# f28e12x_gpio_ctrl_regs register map
Vendor: Texas Instruments
Peripheral module from a debugger description file (folder C2000).
Address unit: 16 bits
Registers are 32-bit, read-write, no defined reset value unless marked. A register's access mark holds for its fields unless they carry their own. Offsets are as the file gives them; lines under a group give offsets from that group; [hi:lo] are bit positions; {n}, {i} and the like mark numbered series; 'fields as' and 'values as' point back to an identical list; <NAME> marks a mode.

## GPIO_CTRL_REGS — GPIO CTRL Registers
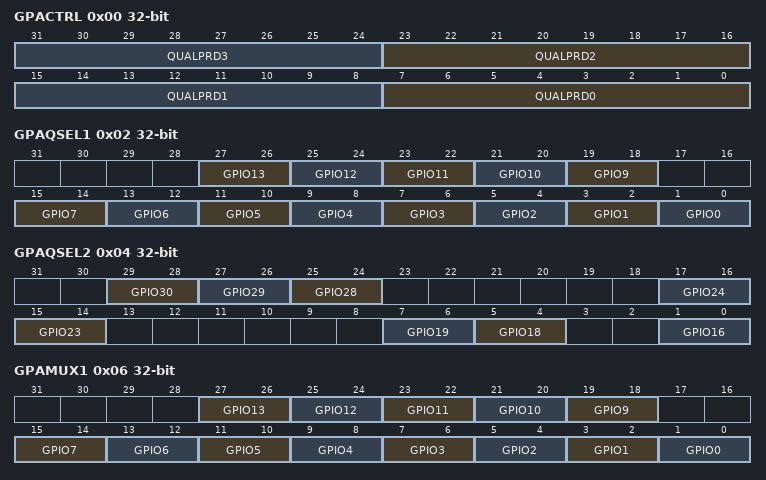
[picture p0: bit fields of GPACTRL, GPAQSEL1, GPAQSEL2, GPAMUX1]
0x00 GPACTRL — GPIO A Qualification Sampling Period Control (GPIO0 to 31)
  [8n+7:8n] QUALPRD{n} (n=0..3) — Qualification sampling period for GPIO{8n} to GPIO{8n+7}
0x02 GPAQSEL1 — GPIO A Qualifier Select 1 Register (GPIO0 to 15)
  [2n+1:2n] GPIO{n} (n=9..13) — Select input qualification type for GPIO{n}
  [2n+1:2n] GPIO{n} (n=0..7) — Select input qualification type for GPIO{n}
0x04 GPAQSEL2 — GPIO A Qualifier Select 2 Register (GPIO16 to 31)
  [29:28] GPIO30 — Select input qualification type for GPIO30
  [27:26] GPIO29 — Select input qualification type for GPIO29
  [25:24] GPIO28 — Select input qualification type for GPIO28
  [17:16] GPIO24 — Select input qualification type for GPIO24
  [15:14] GPIO23 — Select input qualification type for GPIO23
  [7:6] GPIO19 — Select input qualification type for GPIO19
  [5:4] GPIO18 — Select input qualification type for GPIO18
  [1:0] GPIO16 — Select input qualification type for GPIO16
0x06 GPAMUX1 — GPIO A Mux 1 Register (GPIO0 to 15)
  [2n+1:2n] GPIO{n} (n=9..13) — Defines pin-muxing selection for GPIO{n}
  [2n+1:2n] GPIO{n} (n=0..7) — Defines pin-muxing selection for GPIO{n}
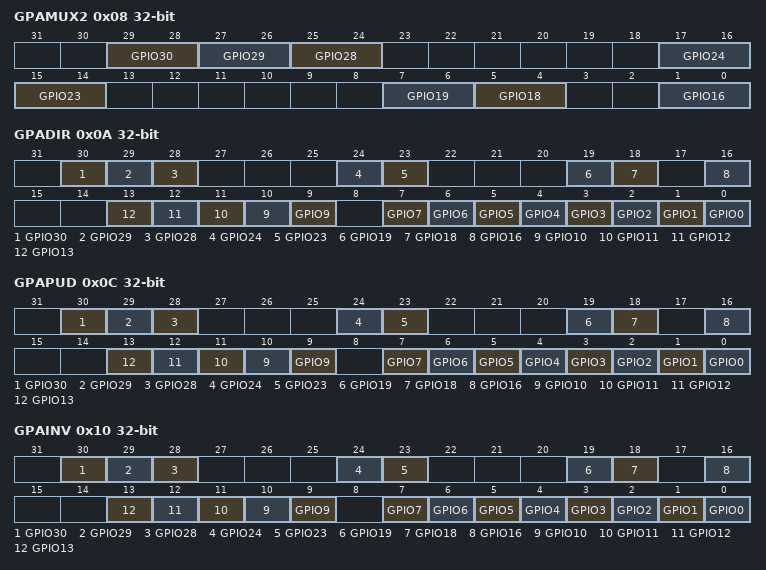
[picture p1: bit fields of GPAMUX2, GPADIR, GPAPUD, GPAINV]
0x08 GPAMUX2 — GPIO A Mux 2 Register (GPIO16 to 31)
  [29:28] GPIO30 — Defines pin-muxing selection for GPIO30
  [27:26] GPIO29 — Defines pin-muxing selection for GPIO29
  [25:24] GPIO28 — Defines pin-muxing selection for GPIO28
  [17:16] GPIO24 — Defines pin-muxing selection for GPIO24
  [15:14] GPIO23 — Defines pin-muxing selection for GPIO23
  [7:6] GPIO19 — Defines pin-muxing selection for GPIO19
  [5:4] GPIO18 — Defines pin-muxing selection for GPIO18
  [1:0] GPIO16 — Defines pin-muxing selection for GPIO16
0x0A GPADIR — GPIO A Direction Register (GPIO0 to 31)
  [30] GPIO30 — Defines direction for this pin in GPIO mode
  [29] GPIO29 — Defines direction for this pin in GPIO mode
  [28] GPIO28 — Defines direction for this pin in GPIO mode
  [24] GPIO24 — Defines direction for this pin in GPIO mode
  [23] GPIO23 — Defines direction for this pin in GPIO mode
  [19] GPIO19 — Defines direction for this pin in GPIO mode
  [18] GPIO18 — Defines direction for this pin in GPIO mode
  [16] GPIO16 — Defines direction for this pin in GPIO mode
  [n] GPIO{n} (n=9..13) — Defines direction for this pin in GPIO mode
  [n] GPIO{n} (n=0..7) — Defines direction for this pin in GPIO mode
0x0C GPAPUD — GPIO A Pull Up Disable Register (GPIO0 to 31)
  [30] GPIO30 — Pull-Up Disable control for this pin
  [29] GPIO29 — Pull-Up Disable control for this pin
  [28] GPIO28 — Pull-Up Disable control for this pin
  [24] GPIO24 — Pull-Up Disable control for this pin
  [23] GPIO23 — Pull-Up Disable control for this pin
  [19] GPIO19 — Pull-Up Disable control for this pin
  [18] GPIO18 — Pull-Up Disable control for this pin
  [16] GPIO16 — Pull-Up Disable control for this pin
  [n] GPIO{n} (n=9..13) — Pull-Up Disable control for this pin
  [n] GPIO{n} (n=0..7) — Pull-Up Disable control for this pin
0x10 GPAINV — GPIO A Input Polarity Invert Registers (GPIO0 to 31)
  [30] GPIO30 — Input inversion control for this pin
  [29] GPIO29 — Input inversion control for this pin
  [28] GPIO28 — Input inversion control for this pin
  [24] GPIO24 — Input inversion control for this pin
  [23] GPIO23 — Input inversion control for this pin
  [19] GPIO19 — Input inversion control for this pin
  [18] GPIO18 — Input inversion control for this pin
  [16] GPIO16 — Input inversion control for this pin
  [n] GPIO{n} (n=9..13) — Input inversion control for this pin
  [n] GPIO{n} (n=0..7) — Input inversion control for this pin
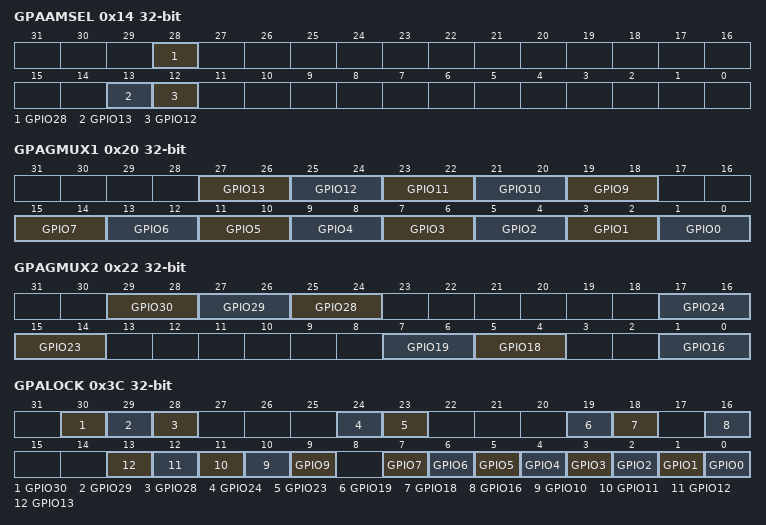
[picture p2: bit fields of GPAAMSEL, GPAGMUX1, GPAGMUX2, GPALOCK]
0x14 GPAAMSEL — GPIO A Analog Mode Select register (GPIO0 to GPIO31)
  [28] GPIO28 — Analog Mode select for this pin
  [13] GPIO13 — Analog Mode select for this pin
  [12] GPIO12 — Analog Mode select for this pin
0x20 GPAGMUX1 — GPIO A Peripheral Group Mux (GPIO0 to 15)
  fields as GPAMUX1
0x22 GPAGMUX2 — GPIO A Peripheral Group Mux (GPIO16 to 31)
  fields as GPAMUX2
0x3C GPALOCK — GPIO A Lock Configuration Register (GPIO0 to 31)
  [30] GPIO30 — Configuration Lock bit for this pin
  [29] GPIO29 — Configuration Lock bit for this pin
  [28] GPIO28 — Configuration Lock bit for this pin
  [24] GPIO24 — Configuration Lock bit for this pin
  [23] GPIO23 — Configuration Lock bit for this pin
  [19] GPIO19 — Configuration Lock bit for this pin
  [18] GPIO18 — Configuration Lock bit for this pin
  [16] GPIO16 — Configuration Lock bit for this pin
  [n] GPIO{n} (n=9..13) — Configuration Lock bit for this pin
  [n] GPIO{n} (n=0..7) — Configuration Lock bit for this pin
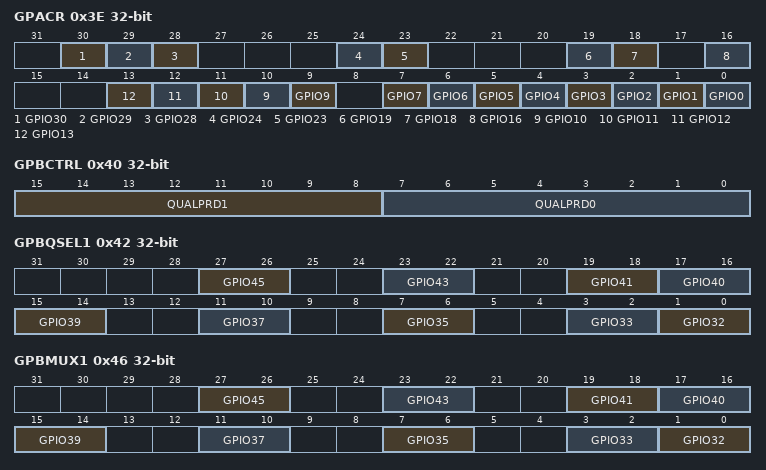
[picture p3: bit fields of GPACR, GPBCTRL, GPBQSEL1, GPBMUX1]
0x3E GPACR — GPIO A Lock Commit Register (GPIO0 to 31)
  [30] GPIO30 — Configuration lock commit bit for this pin
  [29] GPIO29 — Configuration lock commit bit for this pin
  [28] GPIO28 — Configuration lock commit bit for this pin
  [24] GPIO24 — Configuration lock commit bit for this pin
  [23] GPIO23 — Configuration lock commit bit for this pin
  [19] GPIO19 — Configuration lock commit bit for this pin
  [18] GPIO18 — Configuration lock commit bit for this pin
  [16] GPIO16 — Configuration lock commit bit for this pin
  [n] GPIO{n} (n=9..13) — Configuration lock commit bit for this pin
  [n] GPIO{n} (n=0..7) — Configuration lock commit bit for this pin
0x40 GPBCTRL — GPIO B Qualification Sampling Period Control (GPIO32 to 63)
  [15:8] QUALPRD1 — Qualification sampling period for GPIO40 to GPIO47
  [7:0] QUALPRD0 — Qualification sampling period for GPIO32 to GPIO39
0x42 GPBQSEL1 — GPIO B Qualifier Select 1 Register (GPIO32 to 47)
  [27:26] GPIO45 — Select input qualification type for GPIO45
  [23:22] GPIO43 — Select input qualification type for GPIO43
  [19:18] GPIO41 — Select input qualification type for GPIO41
  [17:16] GPIO40 — Select input qualification type for GPIO40
  [15:14] GPIO39 — Select input qualification type for GPIO39
  [11:10] GPIO37 — Select input qualification type for GPIO37
  [7:6] GPIO35 — Select input qualification type for GPIO35
  [3:2] GPIO33 — Select input qualification type for GPIO33
  [1:0] GPIO32 — Select input qualification type for GPIO32
0x44 GPBQSEL2 access not given — GPIO B Qualifier Select 2 Register (GPIO48 to 63)
0x46 GPBMUX1 — GPIO B Mux 1 Register (GPIO32 to 47)
  [27:26] GPIO45 — Defines pin-muxing selection for GPIO45
  [23:22] GPIO43 — Defines pin-muxing selection for GPIO43
  [19:18] GPIO41 — Defines pin-muxing selection for GPIO41
  [17:16] GPIO40 — Defines pin-muxing selection for GPIO40
  [15:14] GPIO39 — Defines pin-muxing selection for GPIO39
  [11:10] GPIO37 — Defines pin-muxing selection for GPIO37
  [7:6] GPIO35 — Defines pin-muxing selection for GPIO35
  [3:2] GPIO33 — Defines pin-muxing selection for GPIO33
  [1:0] GPIO32 — Defines pin-muxing selection for GPIO32
0x48 GPBMUX2 access not given — GPIO B Mux 2 Register (GPIO48 to 63)
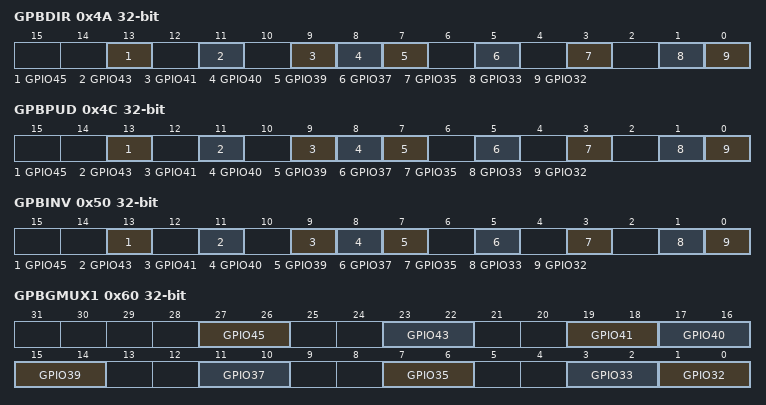
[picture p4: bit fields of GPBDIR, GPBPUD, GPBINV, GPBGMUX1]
0x4A GPBDIR — GPIO B Direction Register (GPIO32 to 63)
  [13] GPIO45 — Defines direction for this pin in GPIO mode
  [11] GPIO43 — Defines direction for this pin in GPIO mode
  [9] GPIO41 — Defines direction for this pin in GPIO mode
  [8] GPIO40 — Defines direction for this pin in GPIO mode
  [7] GPIO39 — Defines direction for this pin in GPIO mode
  [5] GPIO37 — Defines direction for this pin in GPIO mode
  [3] GPIO35 — Defines direction for this pin in GPIO mode
  [1] GPIO33 — Defines direction for this pin in GPIO mode
  [0] GPIO32 — Defines direction for this pin in GPIO mode
0x4C GPBPUD — GPIO B Pull Up Disable Register (GPIO32 to 63)
  [13] GPIO45 — Pull-Up Disable control for this pin
  [11] GPIO43 — Pull-Up Disable control for this pin
  [9] GPIO41 — Pull-Up Disable control for this pin
  [8] GPIO40 — Pull-Up Disable control for this pin
  [7] GPIO39 — Pull-Up Disable control for this pin
  [5] GPIO37 — Pull-Up Disable control for this pin
  [3] GPIO35 — Pull-Up Disable control for this pin
  [1] GPIO33 — Pull-Up Disable control for this pin
  [0] GPIO32 — Pull-Up Disable control for this pin
0x50 GPBINV — GPIO B Input Polarity Invert Registers (GPIO32 to 63)
  [13] GPIO45 — Input inversion control for this pin
  [11] GPIO43 — Input inversion control for this pin
  [9] GPIO41 — Input inversion control for this pin
  [8] GPIO40 — Input inversion control for this pin
  [7] GPIO39 — Input inversion control for this pin
  [5] GPIO37 — Input inversion control for this pin
  [3] GPIO35 — Input inversion control for this pin
  [1] GPIO33 — Input inversion control for this pin
  [0] GPIO32 — Input inversion control for this pin
0x60 GPBGMUX1 — GPIO B Peripheral Group Mux (GPIO32 to 47)
  fields as GPBMUX1
0x62 GPBGMUX2 access not given — GPIO B Peripheral Group Mux (GPIO48 to 63)
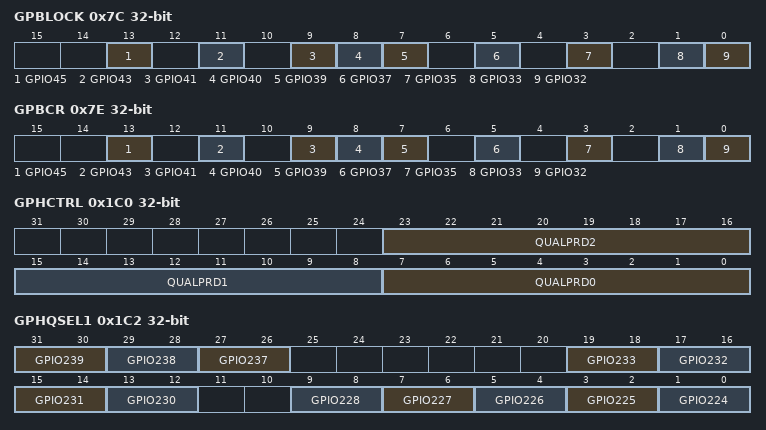
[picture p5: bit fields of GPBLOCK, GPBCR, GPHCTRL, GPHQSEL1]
0x7C GPBLOCK — GPIO B Lock Configuration Register (GPIO32 to 63)
  [13] GPIO45 — Configuration Lock bit for this pin
  [11] GPIO43 — Configuration Lock bit for this pin
  [9] GPIO41 — Configuration Lock bit for this pin
  [8] GPIO40 — Configuration Lock bit for this pin
  [7] GPIO39 — Configuration Lock bit for this pin
  [5] GPIO37 — Configuration Lock bit for this pin
  [3] GPIO35 — Configuration Lock bit for this pin
  [1] GPIO33 — Configuration Lock bit for this pin
  [0] GPIO32 — Configuration Lock bit for this pin
0x7E GPBCR — GPIO B Lock Commit Register (GPIO32 to 63)
  [13] GPIO45 — Configuration lock commit bit for this pin
  [11] GPIO43 — Configuration lock commit bit for this pin
  [9] GPIO41 — Configuration lock commit bit for this pin
  [8] GPIO40 — Configuration lock commit bit for this pin
  [7] GPIO39 — Configuration lock commit bit for this pin
  [5] GPIO37 — Configuration lock commit bit for this pin
  [3] GPIO35 — Configuration lock commit bit for this pin
  [1] GPIO33 — Configuration lock commit bit for this pin
  [0] GPIO32 — Configuration lock commit bit for this pin
0x1C0 GPHCTRL — GPIO H Qualification Sampling Period Control (GPIO224 to 255)
  [23:16] QUALPRD2 — Qualification sampling period for GPIO240 to GPIO247
  [15:8] QUALPRD1 — Qualification sampling period for GPIO232 to GPIO239
  [7:0] QUALPRD0 — Qualification sampling period for GPIO224 to GPIO231
0x1C2 GPHQSEL1 — GPIO H Qualifier Select 1 Register (GPIO224 to 239)
  [31:30] GPIO239 — Select input qualification type for this GPIO Pin
  [29:28] GPIO238 — Select input qualification type for this GPIO Pin
  [27:26] GPIO237 — Select input qualification type for this GPIO Pin
  [2n-447:2n-448] GPIO{n} (n=230..233) — Select input qualification type for this GPIO Pin
  [2n-447:2n-448] GPIO{n} (n=224..228) — Select input qualification type for this GPIO Pin
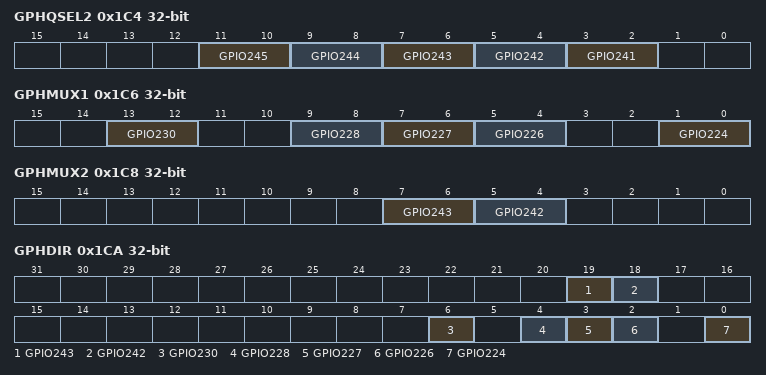
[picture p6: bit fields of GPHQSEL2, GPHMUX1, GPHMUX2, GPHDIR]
0x1C4 GPHQSEL2 — GPIO H Qualifier Select 2 Register (GPIO240 to 255)
  [2n-479:2n-480] GPIO{n} (n=241..245) — Select input qualification type for this GPIO Pin
0x1C6 GPHMUX1 — GPIO H Mux 1 Register (GPIO224 to 239)
  [13:12] GPIO230 — Defines pin-muxing selection for GPIO230
  [9:8] GPIO228 — Defines pin-muxing selection for GPIO228
  [7:6] GPIO227 — Defines pin-muxing selection for GPIO227
  [5:4] GPIO226 — Defines pin-muxing selection for GPIO226
  [1:0] GPIO224 — Defines pin-muxing selection for GPIO224
0x1C8 GPHMUX2 — GPIO H Mux 2 Register (GPIO240 to 255)
  [7:6] GPIO243 — Defines pin-muxing selection for GPIO243
  [5:4] GPIO242 — Defines pin-muxing selection for GPIO242
0x1CA GPHDIR — GPIO H Direction Register (GPIO224 to 255)
  [19] GPIO243 — Defines direction for this pin in GPIO mode
  [18] GPIO242 — Defines direction for this pin in GPIO mode
  [6] GPIO230 — Defines direction for this pin in GPIO mode
  [4] GPIO228 — Defines direction for this pin in GPIO mode
  [3] GPIO227 — Defines direction for this pin in GPIO mode
  [2] GPIO226 — Defines direction for this pin in GPIO mode
  [0] GPIO224 — Defines direction for this pin in GPIO mode
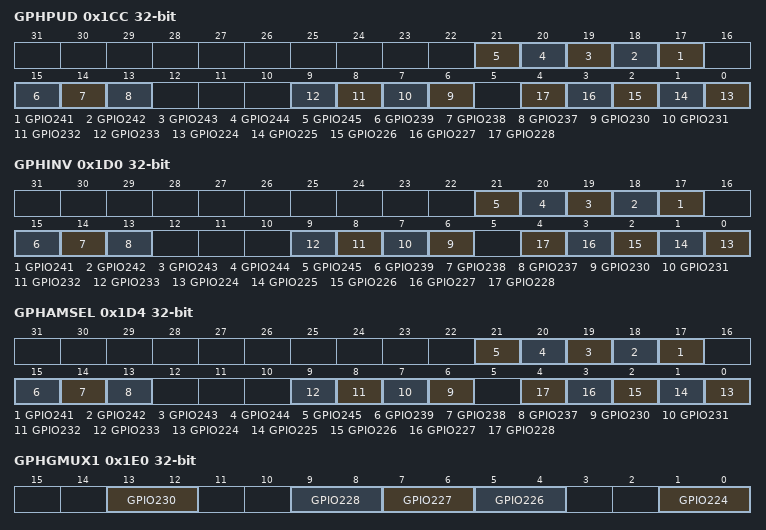
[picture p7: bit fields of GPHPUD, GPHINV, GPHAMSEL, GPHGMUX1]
0x1CC GPHPUD — GPIO H Pull Up Disable Register (GPIO224 to 255)
  [n-224] GPIO{n} (n=241..245) — Pull-Up Disable control for this pin
  [15] GPIO239 — Pull-Up Disable control for this pin
  [14] GPIO238 — Pull-Up Disable control for this pin
  [13] GPIO237 — Pull-Up Disable control for this pin
  [n-224] GPIO{n} (n=230..233) — Pull-Up Disable control for this pin
  [n-224] GPIO{n} (n=224..228) — Pull-Up Disable control for this pin
0x1D0 GPHINV — GPIO H Input Polarity Invert Registers (GPIO224 to 255)
  [n-224] GPIO{n} (n=241..245) — Input inversion control for this pin
  [15] GPIO239 — Input inversion control for this pin
  [14] GPIO238 — Input inversion control for this pin
  [13] GPIO237 — Input inversion control for this pin
  [n-224] GPIO{n} (n=230..233) — Input inversion control for this pin
  [n-224] GPIO{n} (n=224..228) — Input inversion control for this pin
0x1D4 GPHAMSEL — GPIO H Analog Mode Select register (GPIO224 to GPIO255)
  [n-224] GPIO{n} (n=241..245) — Analog Mode select for this pin
  [15] GPIO239 — Analog Mode select for this pin
  [14] GPIO238 — Analog Mode select for this pin
  [13] GPIO237 — Analog Mode select for this pin
  [n-224] GPIO{n} (n=230..233) — Analog Mode select for this pin
  [n-224] GPIO{n} (n=224..228) — Analog Mode select for this pin
0x1E0 GPHGMUX1 — GPIO H Peripheral Group Mux (GPIO224 to 239)
  fields as GPHMUX1
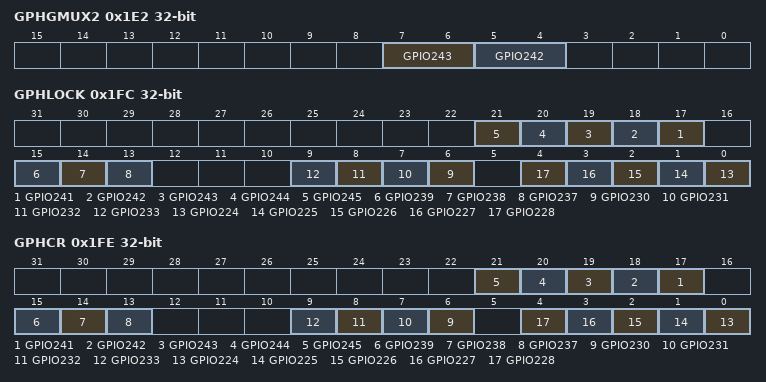
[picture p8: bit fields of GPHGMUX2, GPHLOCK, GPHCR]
0x1E2 GPHGMUX2 — GPIO H Peripheral Group Mux (GPIO240 to 255)
  fields as GPHMUX2
0x1FC GPHLOCK — GPIO H Lock Configuration Register (GPIO224 to 255)
  [n-224] GPIO{n} (n=241..245) — Configuration Lock bit for this pin
  [15] GPIO239 — Configuration Lock bit for this pin
  [14] GPIO238 — Configuration Lock bit for this pin
  [13] GPIO237 — Configuration Lock bit for this pin
  [n-224] GPIO{n} (n=230..233) — Configuration Lock bit for this pin
  [n-224] GPIO{n} (n=224..228) — Configuration Lock bit for this pin
0x1FE GPHCR — GPIO H Lock Commit Register (GPIO224 to 255)
  [n-224] GPIO{n} (n=241..245) — Configuration lock commit bit for this pin
  [15] GPIO239 — Configuration lock commit bit for this pin
  [14] GPIO238 — Configuration lock commit bit for this pin
  [13] GPIO237 — Configuration lock commit bit for this pin
  [n-224] GPIO{n} (n=230..233) — Configuration lock commit bit for this pin
  [n-224] GPIO{n} (n=224..228) — Configuration lock commit bit for this pin
